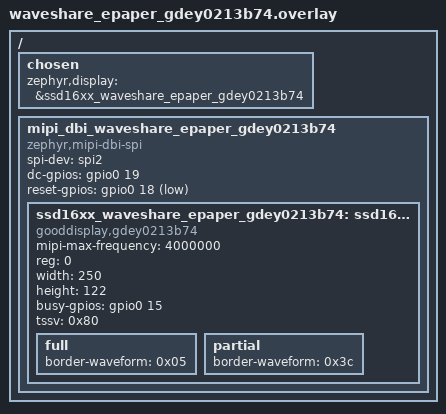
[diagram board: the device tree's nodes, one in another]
/*
 * Copyright (c) 2024, Kelly Helmut Lord
 *
 * SPDX-License-Identifier: Apache-2.0
 */

#include "waveshare_epaper_common.dtsi"
#include <zephyr/dt-bindings/gpio/arduino-header-r3.h>

/ {
	chosen {
		zephyr,display = &ssd16xx_waveshare_epaper_gdey0213b74;
	};

	mipi_dbi_waveshare_epaper_gdey0213b74 {
		compatible = "zephyr,mipi-dbi-spi";

		spi-dev = <&spi2>;
		dc-gpios = <&gpio0 19 GPIO_ACTIVE_HIGH>;	/* D19 */
		reset-gpios = <&gpio0 18 GPIO_ACTIVE_LOW>;	/* D18 */
		#address-cells = <1>;
		#size-cells = <0>;

		ssd16xx_waveshare_epaper_gdey0213b74: ssd16xxfb@0 {
			compatible = "gooddisplay,gdey0213b74", "solomon,ssd1680";
			mipi-max-frequency = <4000000>;
			reg = <0>;
			width = <250>;
			height = <122>;

			busy-gpios = <&gpio0 15 GPIO_ACTIVE_HIGH>;	/* D15 */

			tssv = <0x80>;

			full {
				border-waveform = <0x05>;
			};

			partial {
				border-waveform = <0x3c>;
			};
		};
	};
};
